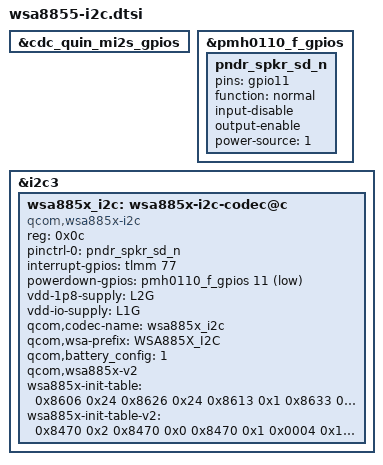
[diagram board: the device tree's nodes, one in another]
/*
 * Copyright (c) Qualcomm Technologies, Inc. and/or its subsidiaries.
 * SPDX-License-Identifier: BSD-3-Clause-Clear
*/

#include <dt-bindings/gpio/gpio.h>

&cdc_quin_mi2s_gpios {
	status = "okay";
};

&pmh0110_f_gpios {
	pndr_spkr_sd_n: pndr_spkr_sd_n {
		pins = "gpio11";
		function = "normal";
		input-disable;
		output-enable;
		power-source = <1>;
	};
};

&i2c3 {
	wsa885x_i2c: wsa885x-i2c-codec@c {
		compatible = "qcom,wsa885x-i2c";
		reg = <0x0c>;
		pinctrl-names = "default";
		pinctrl-0 = <&pndr_spkr_sd_n>;
		interrupt-gpios = <&tlmm 77 GPIO_ACTIVE_HIGH>;
		powerdown-gpios = <&pmh0110_f_gpios 11 GPIO_ACTIVE_LOW>;
		vdd-1p8-supply = <&L2G>;
		vdd-io-supply = <&L1G>;
		qcom,codec-name = "wsa885x_i2c";
		qcom,wsa-prefix = "WSA885X_I2C";
		qcom,battery_config = <1>;
		qcom,wsa885x-v2;
		wsa885x-init-table =
			<0x8606 0x24  /* CDC_RX0_RX_PATH_CTL - CLK_EN(1) */
			0x8626 0x24  /* CDC_RX1_RX_PATH_CTL - CLK_EN(1) */
			0x8613 0x1   /* RX0_RX_PATH_DSMDEM_CTL - DSMDEM_CLK_EN(1) */
			0x8633 0x1   /* RX1_RX_PATH_DSMDEM_CTL - DSMDEM_CLK_EN(1) */
			0x8640 0x1   /* CDC_COMPANDER0_CTL0 - CLK_EN(1) */
			0x8660 0x1   /* CDC_COMPANDER1_CTL0 - CLK_EN(1) */
			0x86A1 0x14  /* CDC_VSENSE0_SPKR_PROT_PATH_CTL - CLK_EN(1) */
			0x86B1 0x14  /* CDC_VSENSE1_SPKR_PROT_PATH_CTL - CLK_EN(1)*/
			0x86A9 0x14  /* CDC_ISENSE0_SPKR_PROT_PATH_CTL - CLK_EN(1) */
			0x86B9 0x14  /* CDC_ISENSE1_SPKR_PROT_PATH_CTL - CLK_EN(1) */
			0x841C 0xF   /* DIG_CTRL0_CDC_CLK_CTL  - SYS_CLOCK_EN(1) */
			0x841C 0x4F  /* DIG_CTRL0_CDC_CLK_CTL - FSM_INTP_CG_DISABLE */
			0x8470 0x2   /* DIG_CTRL0_CDC_RXTX_FSCNT_CTL - FS_CNT_CLR(1) */
			0x8470 0x0   /* DIG_CTRL0_CDC_RXTX_FSCNT_CTL - FS_CNT_CLR(0) */
			0x8470 0x1   /* DIG_CTRL0_CDC_RXTX_FSCNT_CTL - FS_CNT_EN(1) */
			0x0004 0x1   /* SMP_AMP_CTRL_STEREO_CMT_GRP_MASK - CMT_GRP_MASK(1) */
			0x8602 0x60  /* CDC_RX0_RX_PATH_CFG1 - HPF_EN(0) */
			0x8622 0x60  /* CDC_RX1_RX_PATH_CFG1 - HPF_EN(0) */
			0x8108 0xA5  /* PANDEIRO_ANA_TOP_SPK_TOP_PWRSTG_CH1_CTRL3 */
			0x810E 0xA5  /* PANDEIRO_ANA_TOP_SPK_TOP_PWRSTG_CH2_CTRL3 */
			0x80CA 0x85  /* PANDEIRO_ANA_TOP_IVSENSE_ADC_MODE_CTL2 - SPARE_BITS_0(Sets LDO to 1.6V) */
			0x80CB 0xC   /* PANDEIRO_ANA_TOP_IVSENSE_ADC_MODE_CTL3 - ADC_VREF_VCTL_I(Sets VREF_I to 1.35V) */
			0x80CB 0xE   /* PANDEIRO_ANA_TOP_IVSENSE_ADC_MODE_CTL3 - ADC_VREF_VCTL_I(Sets VREF_I to 1.35V) */
			0x80CC 0xC   /* PANDEIRO_ANA_TOP_IVSENSE_ADC_REF_CTL - ADC_VREF_VCTL_V(Sets VREF_V to 1.35V) */
			0x84B4 0x1   /* PANDEIRO_DIG_CTRL0_GAIN_RAMP0_CTL1 - ANA_BYPASS(1) */
			0x84B7 0x1   /* PANDEIRO_DIG_CTRL0_GAIN_RAMP1_CTL1 - ANA_BYPASS(1) */
			0x8601 0x88  /* CDC_RX0_RX_PATH_CFG0 - DLY_ZN_EN(1) */
			0x8601 0x89  /* CDC_RX0_RX_PATH_CFG0 - PH_EQ_EN */
			0x8621 0x88  /* CDC_RX1_RX_PATH_CFG0 - DLY_ZN_EN(1) */
			0x8621 0x89  /* CDC_RX1_RX_PATH_CFG0 - PH_EQ_EN */
			0x805B 0x82  /* PANDEIRO_ANA_TOP_BOOST_STB_CTRL2 */
			0x805C 0x34  /* PANDEIRO_ANA_TOP_BOOST_STB_CTRL3 */
			0x8065 0x41  /* PANDEIRO_ANA_TOP_BOOST_PWRSTAGE_CTRL2 */
			0x8067 0x7F  /* PANDEIRO_ANA_TOP_BOOST_PWRSTAGE_CTRL4 */
			0x86CD 0x50  /* CDC_CLSH_V1P8_BP_CTL1 */
			0x86CC 0x6C  /* CDC_CLSH_V1P8_BP_CTL0 */
			0x86C7 0xD   /* CDC_CLSH_CLSH_SIG_DP_CTL0 */
			0x86C3 0x3   /* CDC_CLSH_CLSH_V_HD_PA */
			0x8423 0x5   /* PANDEIRO_DIG_CTRL0_POWER_FSM_CTL0 */
			0x800D 0x20   /* PANDEIRO_DIG_CTRL0_POWER_FSM_CTL0 BST_CLK_FLIP_EN(Boost enable FSM issue(Work around for I2S mode, flip boost div2 clk)) */
			0x810B 0x45  /* PANDEIRO_ANA_TOP_SPK_TOP_PWRSTG_CH1_TUNE3 */
			0x8111 0x45  /* PANDEIRO_ANA_TOP_SPK_TOP_PWRSTG_CH2_TUNE3 */
			0x86CE 0x5   /* CDC_CLSH_V1P8_BP_CTL2 - BP_CNT  */
			0x8024 0x35  /* PANDEIRO_ANA_TOP_BG_TVP_UVLO1_PROG - VTH 2.1v */
			0x8025 0x21  /* PANDEIRO_ANA_TOP_BG_TVP_UVLO2_PROG - VTH 2.0v */
			0x805E 0xC7  /* PANDEIRO_ANA_TOP_BOOST_BYP_CTRL2 */
			0x805F 0x11  /* PANDEIRO_ANA_TOP_BOOST_BYP_CTRL3 */
			0x80D0 0x80 /* PANDEIRO_ANA_TOP_IVSENSE_ADC_CDAC_CAL_CTL2 */
			0x813C 0x08 /* PANDEIRO_ANA_TOP_SPK_TOP_SPARE3 */
			0x842B 0x47 /* PANDEIRO_DIG_CTRL0_PA0_FSM_CTL1 - SILENT_STATE_IVS_EN */
			0x8435 0x47 /* PANDEIRO_DIG_CTRL0_PA1_FSM_CTL1 - SILENT_STATE_IVS_EN */
			0x8647 0x34 /* CDC_COMPANDER0_CTL7 - AGAIN_DELAY */
			0x8667 0x34 /* CDC_COMPANDER1_CTL7 - AGAIN_DELAY */
			0x8458 0x79>; /* PANDEIRO_DIG_CTRL0_VBAT_THRM_FLT_CTL - VBAT_COEF_SEL */

		wsa885x-init-table-v2 =
			<0x8470 0x2   /* DIG_CTRL0_CDC_RXTX_FSCNT_CTL - FS_CNT_CLR(1) */
			0x8470 0x0   /* DIG_CTRL0_CDC_RXTX_FSCNT_CTL - FS_CNT_CLR(0) */
			0x8470 0x1   /* DIG_CTRL0_CDC_RXTX_FSCNT_CTL - FS_CNT_EN(1) */
			0x0004 0x1   /* SMP_AMP_CTRL_STEREO_CMT_GRP_MASK - CMT_GRP_MASK(1) */
			0x8602 0x60  /* CDC_RX0_RX_PATH_CFG1 - HPF_EN(0) */
			0x8622 0x60  /* CDC_RX1_RX_PATH_CFG1 - HPF_EN(0) */
			0x8458 0x79  /* PANDEIRO_DIG_CTRL0_VBAT_THRM_FLT_CTL - VBAT_COEF_SEL */
			0x810B 0xD9  /* PANDEIRO_ANA_TOP_SPK_TOP_PWRSTG_CH1_TUNE3 */
			0x8111 0xD9  /* PANDEIRO_ANA_TOP_SPK_TOP_PWRSTG_CH2_TUNE3 */
			0x813C 0x08  /* SPK_TOP_COMMON_CTRL4 - override_ctl*/
			0x8102 0x04  /* PANDEIROI2S.TOP.PANDEIRO_ANA_TOP.SPK_TOP_COMMON_CTRL2.LDO_PROG */
			0x811C 0x29  /* PANDEIROI2S.TOP.PANDEIRO_ANA_TOP.SPK_TOP_LF_CH1_CTRL11.PHASE90(Add 90 degree phase shift between PWM clock of CH1 and CH2.) */
			0x811D 0x40  /* PANDEIRO_ANA_TOP_SPK_TOP_LF_CH1_TUNE1  - HIZ_DELAY_PROG*/
			0x8129 0x40  /* PANDEIRO_ANA_TOP_SPK_TOP_LF_CH2_TUNE1  - HIZ_DELAY_PROG*/
			0x811A 0x80  /* PANDEIRO_ANA_TOP_SPK_TOP_LF_CH1_CTRL9 - OCP_CLIP_T_CTRL_EXT */
			0x8126 0x80  /* PANDEIRO_ANA_TOP_SPK_TOP_LF_CH2_CTRL9 -  OCP_CLIP_T_CTRL_EXT */
			0x8103 0x6   /* PANDEIRO_ANA_TOP_SPK_TOP_COMMON_TUNE1 - GAIN_TUNE */
			0x80CA 0x85  /* PANDEIRO_ANA_TOP_IVSENSE_ADC_MODE_CTL2 - SPARE_BITS_0(Sets LDO to 1.6V) */
			0x80CB 0xE   /* PANDEIRO_ANA_TOP_IVSENSE_ADC_MODE_CTL3 - ADC_VREF_VCTL_I(Sets VREF_I to 1.35V) */
			0x80CC 0xC   /* PANDEIRO_ANA_TOP_IVSENSE_ADC_REF_CTL - ADC_VREF_VCTL_V(Sets VREF_V to 1.35V) */
			0x80D0 0x80 /* PANDEIRO_ANA_TOP_IVSENSE_ADC_CDAC_CAL_CTL2 */
			0x80BA 0xC0 /* PANDEIROI2S.TOP.PANDEIRO_ANA_TOP.SPK_TOP_SPARE3(force the VDDSPK_LV_READY from analog to be high) */
			0x841C 0x4E /* PANDEIROI2S.TOP.PANDEIRO_DIG_CTRL0_PANDEIRO_DIG_CTRL0.CDC_CLK_CTL.FSM_INTP_CG_DISABLE */
			0x8435 0x47 /* PANDEIRO_DIG_CTRL0_PA1_FSM_CTL1 - SILENT_STATE_IVS_EN */
			0x86CE 0x09 /* PANDEIROI2S.TOP.CDC_CLSH_CDC_CLSH.V1P8_BP_CTL2.BP_CNT */
			0x8667 0x34 /* CDC_COMPANDER1_CTL7 - AGAIN_DELAY */
			0x800D 0x08>; /* PANDEIROI2S.TOP.PANDEIRO_ANA_TOP.PON_CKSK_CTL_0 */
	};
};
